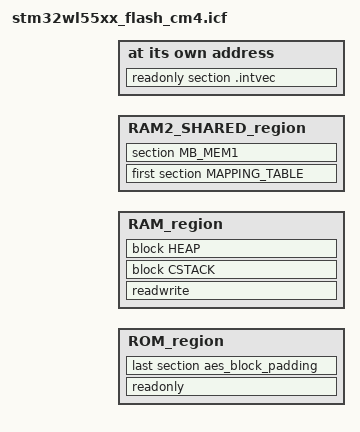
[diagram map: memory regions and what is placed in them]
/*###ICF### Set of symbols used in UserApp project ****/

define memory mem with size = 4G;

/******************************************************************************/
/*       Include of SBSFU symbols file                                        */
/*   (Project>Options>Linker>Extra Options --config_search option is used to  */
/*   specify the the directory to search for include files                    */
/******************************************************************************/
include "mapping_sbsfu.icf";
include "mapping_fwimg.icf";

/*-Memory Regions-*/
/***** FLASH part dedicated to M4 *****/
define symbol __ICFEDIT_region_ROM_start__               = __ICFEDIT_SLOT_Active_2_start__ + 512;
define symbol __ICFEDIT_region_ROM_end__                 = __ICFEDIT_SLOT_Active_2_end__;
/***** SRAM1 dedicated to M4 *****/
define symbol __ICFEDIT_region_RAM_start__               = __ICFEDIT_M4_APP_region_RAM_start__;
define symbol __ICFEDIT_region_RAM_end__                 = __ICFEDIT_M4_APP_region_RAM_end__;
/***** SRAM2 shared allocated by M4 *****/
define symbol __ICFEDIT_region_RAM2_SHARED_start__       = __ICFEDIT_M4_SHARED_region_SRAM_start__;
define symbol __ICFEDIT_region_RAM2_SHARED_end__         = __ICFEDIT_M4_SHARED_region_SRAM_end__;

/*-Sizes-*/
define symbol __ICFEDIT_size_cstack__ = 0x1000;
define symbol __ICFEDIT_size_heap__ = 0x200;

define region ROM_region      = mem:[from __ICFEDIT_region_ROM_start__   to __ICFEDIT_region_ROM_end__];
define region RAM_region      = mem:[from __ICFEDIT_region_RAM_start__   to __ICFEDIT_region_RAM_end__];
define region RAM2_SHARED_region = mem:[from __ICFEDIT_region_RAM2_SHARED_start__  to __ICFEDIT_region_RAM2_SHARED_end__];

/* to make sure the binary size is a multiple of the AES block size (16 bytes) and L4 flash writing unit (8 bytes) */
define root section aes_block_padding with alignment=16
{
udata8 "Force Alignment";
pad_to 16;
};

define block CSTACK    with alignment = 8, size = __ICFEDIT_size_cstack__   { };
define block HEAP      with alignment = 8, size = __ICFEDIT_size_heap__     { };

initialize by copy { readwrite };
do not initialize  { section .noinit,
                     section MAPPING_TABLE,
                     section MB_MEM1 };

place at address mem:__ICFEDIT_region_ROM_start__ { readonly section .intvec };

place in ROM_region   { readonly, last section aes_block_padding };
place in RAM_region   { readwrite,
                        block CSTACK, block HEAP };
place in RAM2_SHARED_region   { first section MAPPING_TABLE};
place in RAM2_SHARED_region   { section MB_MEM1};
